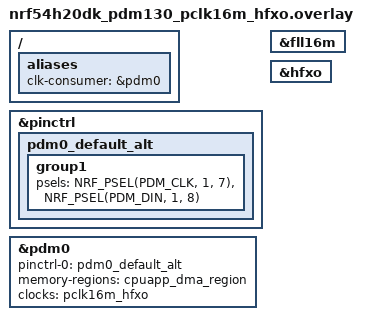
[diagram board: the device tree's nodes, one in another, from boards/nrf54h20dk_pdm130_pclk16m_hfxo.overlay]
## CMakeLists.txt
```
# SPDX-License-Identifier: Apache-2.0

cmake_minimum_required(VERSION 3.28.0)

find_package(Zephyr REQUIRED HINTS $ENV{ZEPHYR_BASE})
project(clock_control_states)

target_sources(app PRIVATE src/main.c)
```

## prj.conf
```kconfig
# The sample requests a clock producer through the clock control API. The interesting part
# is per case: see the overlays (and conf files, where extra Kconfig is needed) under
# boards/ and the scenarios in tests.yaml. Each case selects a consumer via the clk-consumer
# alias and points its clocks property at a SoC clock state.
CONFIG_CLOCK_CONTROL=y
```

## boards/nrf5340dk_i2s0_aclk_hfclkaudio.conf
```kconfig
# Use the split clock control driver (nordic,nrf-clock-hfclkaudio) rather than the legacy
# CLOCK_CONTROL_NRF, since the aclk_hfclkaudio state's producer is the &hfclkaudio device that the
# sample requests through the clock control API.
CONFIG_CLOCK_CONTROL_NRF=n
```

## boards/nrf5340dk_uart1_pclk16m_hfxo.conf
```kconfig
# Use the split clock control driver (nordic,nrf-clock-hfclk) rather than the legacy
# CLOCK_CONTROL_NRF, since the pclk16m_hfxo state's producer is the &hfclk device that the
# sample requests through the clock control API.
CONFIG_CLOCK_CONTROL_NRF=n
```

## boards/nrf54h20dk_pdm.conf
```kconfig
# Compile the PDM (DMIC) driver so the clock-state prototype in dmic_nrfx_pdm.c is instantiated for
# the selected pdm node. The sample still only reads the clock state and requests the producer (if
# any) through the clock control API; the driver derives the same mux/producer/frequency at build
# time.
CONFIG_AUDIO_DMIC=y
```

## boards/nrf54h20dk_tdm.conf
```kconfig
# Compile the TDM driver so the clock-state prototype in i2s_nrf_tdm.c is instantiated for the
# selected tdm node. The sample still only reads the clock state(s) and requests the producer(s)
# through the clock control API; the driver derives the same mux/producer/frequency at build time.
CONFIG_I2S=y
```

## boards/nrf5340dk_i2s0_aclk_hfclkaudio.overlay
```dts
/*
 * Case: nRF5340, i2s0 as the consumer, audio clock sourced from the HFXO-backed audio PLL.
 *
 * i2s0 is only used to carry the clock state; the sample does not operate the I2S. The
 * aclk_hfclkaudio state names the audio-clock signal and the hfclkaudio producer
 * (nordic,nrf-clock-hfclkaudio), which the sample requests through the clock control API. The
 * signal frequency defaults to the SoC value; override &aclk (and, once the driver is aligned,
 * the producer rate) here to pick a different audio frequency.
 */
/ {
	aliases {
		clk-consumer = &i2s0;
	};
};

&i2s0 {
	clocks = <&aclk_hfclkaudio>;
};
```

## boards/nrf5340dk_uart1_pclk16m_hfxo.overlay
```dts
/*
 * Case: nRF5340, uart1 as the consumer, 16 MHz base with the HFXO requested as a producer.
 *
 * uart1 is only used to carry the clock state; the sample does not operate the UARTE. The
 * pclk16m_hfxo state runs at 16 MHz and names HFCLK (and thus the HFXO) as its producer,
 * which the sample requests through the clock control API.
 */
/ {
	aliases {
		clk-consumer = &uart1;
	};
};

&uart1 {
	clocks = <&pclk16m_hfxo>;
};

&hfclk {
	status = "okay";
};
```

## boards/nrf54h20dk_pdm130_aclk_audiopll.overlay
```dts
/*
 * Case: nRF54H20, pdm130 (pdm0) as the consumer, base clock on the audio clock (ACLK) from the
 * audiopll.
 *
 * pdm0 is only used to carry the clock state; the sample does not operate the PDM. The
 * aclk_audiopll state maps to the ACLK mux position and names the audiopll producer, which the PDM
 * driver requests. The base frequency comes from the audiopll's clock-frequency (its audio rate in
 * Hz).
 */
/ {
	aliases {
		clk-consumer = &pdm0;
	};
};

&pinctrl {
	pdm0_default_alt: pdm0_default_alt {
		group1 {
			psels = <NRF_PSEL(PDM_CLK, 1, 7)>,
				<NRF_PSEL(PDM_DIN, 1, 8)>;
		};
	};
};

&audiopll {
	status = "okay";
};

&pdm0 {
	status = "okay";
	pinctrl-0 = <&pdm0_default_alt>;
	pinctrl-names = "default";
	memory-regions = <&cpuapp_dma_region>;
	clocks = <&aclk_audiopll>;
};
```

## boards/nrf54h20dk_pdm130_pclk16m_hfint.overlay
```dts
/*
 * Case: nRF54H20, pdm130 (pdm0) as the consumer, base clock on the 16 MHz peripheral clock (PCLK)
 * from fll16m in its open-loop (low-accuracy) default.
 *
 * pdm0 is only used to carry the clock state; the sample does not operate the PDM. The
 * pclk16m_hfint state maps to the PCLK mux position and, having no producer, takes no clock action
 * (fll16m open-loop is the automatic default).
 */
/ {
	aliases {
		clk-consumer = &pdm0;
	};
};

&pinctrl {
	pdm0_default_alt: pdm0_default_alt {
		group1 {
			psels = <NRF_PSEL(PDM_CLK, 1, 7)>,
				<NRF_PSEL(PDM_DIN, 1, 8)>;
		};
	};
};

&pdm0 {
	status = "okay";
	pinctrl-0 = <&pdm0_default_alt>;
	pinctrl-names = "default";
	memory-regions = <&cpuapp_dma_region>;
	clocks = <&pclk16m_hfint>;
};
```

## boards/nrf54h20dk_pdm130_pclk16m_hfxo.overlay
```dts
/*
 * Case: nRF54H20, pdm130 (pdm0) as the consumer, base clock on the 16 MHz peripheral clock (PCLK)
 * with fll16m driven from the HFXO for crystal accuracy.
 *
 * pdm0 is only used to carry the clock state; the sample does not operate the PDM. The
 * pclk16m_hfxo state maps to the PCLK mux position and names the fll16m producer, requested so it
 * locks to the HFXO.
 */
/ {
	aliases {
		clk-consumer = &pdm0;
	};
};

&pinctrl {
	pdm0_default_alt: pdm0_default_alt {
		group1 {
			psels = <NRF_PSEL(PDM_CLK, 1, 7)>,
				<NRF_PSEL(PDM_DIN, 1, 8)>;
		};
	};
};

&fll16m {
	status = "okay";
};

&hfxo {
	status = "okay";
};

&pdm0 {
	status = "okay";
	pinctrl-0 = <&pdm0_default_alt>;
	pinctrl-names = "default";
	memory-regions = <&cpuapp_dma_region>;
	clocks = <&pclk16m_hfxo>;
};
```

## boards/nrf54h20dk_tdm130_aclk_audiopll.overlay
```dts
/*
 * Case: nRF54H20, tdm130 as the consumer, SCK/MCK on the audio clock (ACLK) from the audiopll.
 *
 * tdm130 is only used to carry the clock state; the sample does not operate the TDM. The single
 * aclk_audiopll state applies to both SCK and MCK: it maps to the ACLK mux position and names the
 * audiopll producer, which the TDM driver requests. The base frequency comes from the audiopll's
 * clock-frequency (its audio rate in Hz).
 */
/ {
	aliases {
		clk-consumer = &tdm130;
	};
};

&pinctrl {
	tdm130_default_alt: tdm130_default_alt {
		group1 {
			psels = <NRF_PSEL(TDM_SCK_M, 1, 3)>,
				<NRF_PSEL(TDM_FSYNC_M, 1, 6)>,
				<NRF_PSEL(TDM_SDOUT, 1, 4)>,
				<NRF_PSEL(TDM_SDIN, 1, 5)>,
				<NRF_PSEL(TDM_MCK, 1, 7)>;
		};
	};
};

&audiopll {
	status = "okay";
};

&tdm130 {
	status = "okay";
	pinctrl-0 = <&tdm130_default_alt>;
	pinctrl-names = "default";
	memory-regions = <&cpuapp_dma_region>;
	mck-frequency = <11289600>;
	clocks = <&aclk_audiopll>;
};
```

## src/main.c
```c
/*
 * Copyright (c) 2026 Nordic Semiconductor ASA
 *
 * SPDX-License-Identifier: Apache-2.0
 */

#include <stdio.h>
#include <zephyr/device.h>
#include <zephyr/drivers/clock_control/nrf_clock_control.h>
#include <soc.h>

/* The clock consumer is selected per case with the clk-consumer alias. The sample only reads the
 * node's clock state(s) (its `clocks` property): for each it learns the frequency the consumer is
 * clocked at and, when the state names a producer, requests that producer through the clock
 * control API. It never operates the peripheral itself.
 *
 * A consumer may reference one or two states. Two states model a peripheral with two independent
 * clock signals, such as the TDM SCK (index 0) and MCK (index 1); a single state applies to the
 * whole consumer. This mirrors how the driver derives the mux position and the producer(s) to
 * request from the very same states.
 */
#define CLK_CONSUMER_NODE DT_ALIAS(clk_consumer)

/* Request the producer of a selected state and immediately release it. A real driver holds the
 * request for as long as the peripheral is clocked.
 */
static __maybe_unused void demo_producer(const char *role, const struct device *clk,
					 const struct nrf_clock_spec *spec)
{
	int err;

	if (!device_is_ready(clk)) {
		printf("  %s: producer %s is not ready\n", role, clk->name);
		return;
	}

	/* The specification is taken from the selected clock state: when it carries producer-*
	 * properties they name the configuration to request (for example an accuracy that selects
	 * a specific source); otherwise it is NULL, leaving every attribute unconstrained so the
	 * producer is simply started. request_sync() blocks until it is running.
	 */
	err = nrf_clock_control_request_sync(clk, spec, K_FOREVER);
	if (err < 0) {
		printf("  %s: failed to request %s: %d\n", role, clk->name, err);
		return;
	}
	if (spec != NULL) {
		printf("  %s: requested producer %s (freq %u Hz, accuracy %u ppm, precision %u)\n",
		       role, clk->name, (unsigned int)spec->frequency,
		       (unsigned int)spec->accuracy, (unsigned int)spec->precision);
	} else {
		printf("  %s: requested producer %s (default spec)\n", role, clk->name);
	}

	err = nrf_clock_control_release(clk, spec);
	if (err < 0) {
		printf("  %s: failed to release %s: %d\n", role, clk->name, err);
		return;
	}
	printf("  %s: released producer %s\n", role, clk->name);
}

/* Pointer to a compound-literal nrf_clock_spec built from the state's producer-* properties, or
 * NULL when the state carries no spec. The literal lives for the duration of the enclosing call.
 */
#define CLK_SPEC_PTR(idx)                                                                          \
	COND_CODE_1(NRF_DT_CLK_HAS_SPEC_BY_IDX(CLK_CONSUMER_NODE, idx),                             \
		    (&(const struct nrf_clock_spec)NRF_DT_CLK_SPEC_BY_IDX(CLK_CONSUMER_NODE, idx)), \
		    (NULL))

#define REPORT(role, idx)                                                                          \
	printf("  %s (clocks[%d]): %u Hz, %s\n", role, idx,                                         \
	       (unsigned int)NRF_PERIPH_GET_FREQUENCY_BY_IDX(CLK_CONSUMER_NODE, idx),               \
	       NRF_DT_CLK_PRESENT_BY_IDX(CLK_CONSUMER_NODE, idx) ? "has producer" : "no producer")

int main(void)
{
	printf("Clock control producer sample on %s\n", CONFIG_BOARD_TARGET);
	printf("Consumer %s\n", DT_NODE_FULL_NAME(CLK_CONSUMER_NODE));

#if DT_CLOCKS_HAS_IDX(CLK_CONSUMER_NODE, 1)
	/* Two clock states: index 0 is SCK, index 1 is MCK. */
	REPORT("SCK", 0);
	REPORT("MCK", 1);
#if NRF_DT_CLK_PRESENT_BY_IDX(CLK_CONSUMER_NODE, 0)
	demo_producer("SCK", NRF_DT_CLK_DEV_BY_IDX(CLK_CONSUMER_NODE, 0), CLK_SPEC_PTR(0));
#endif
#if NRF_DT_CLK_PRESENT_BY_IDX(CLK_CONSUMER_NODE, 1)
	demo_producer("MCK", NRF_DT_CLK_DEV_BY_IDX(CLK_CONSUMER_NODE, 1), CLK_SPEC_PTR(1));
#endif
#else
	/* A single state (or a plain clock) applies to the whole consumer. */
	REPORT("clock", 0);
#if NRF_DT_CLK_PRESENT(CLK_CONSUMER_NODE)
	demo_producer("clock", NRF_DT_CLK_DEV(CLK_CONSUMER_NODE), CLK_SPEC_PTR(0));
#endif
#endif

	return 0;
}
```
